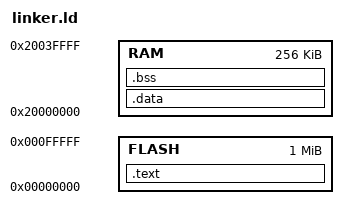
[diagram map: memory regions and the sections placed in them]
ENTRY(Reset_Handler)
MEMORY {
    FLASH : ORIGIN = 0x00000000, LENGTH = 1024K
    RAM : ORIGIN = 0x20000000, LENGTH = 256K
}
SECTIONS {
    .text : { *(.text) } > FLASH
    .data : { *(.data) } > RAM
    .bss : { *(.bss) } > RAM
}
